# N32G41x register map
Vendor: Nsingtech Ltd.; File version: 1.0
CPU: CM4 r0p1, little endian, no MPU, no FPU, 4 interrupt priority bits
Registers are 32-bit, read-write, reset 0x0 unless marked. A register's access mark holds for its fields unless they carry their own. Offsets are from the block's base; [hi:lo] are bit positions.

## IWDG — Independent Watchdog
Base 0x40003000
0x00 IWDG_KEY
  [15:0] KEYV — Key value
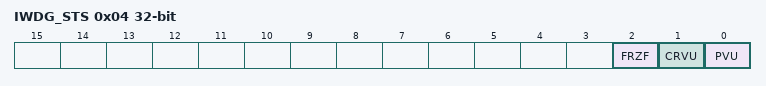
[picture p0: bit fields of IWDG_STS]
0x04 IWDG_STS ro — IWDG Status Register
  [2] FRZF — IWDG freeze flag
  [1] CRVU — Watchdog reload value update
  [0] PVU — Watchdog prescaler value update
0x08 IWDG_PREDIV — IWDG Prescaler Register
  [2:0] PD — Prescaler divider
0x0C IWDG_RELV reset 0xFFF — IWDG Reload Register
  [11:0] REL — Watchdog counter reload value

## SPI1_I2S — Serial Peripheral Interface 1
Base 0x40013000
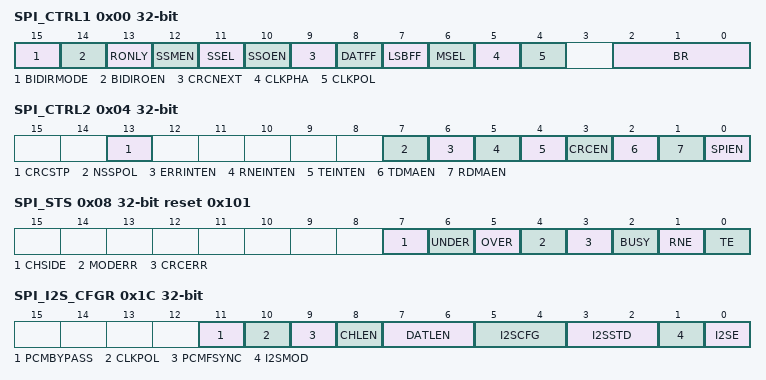
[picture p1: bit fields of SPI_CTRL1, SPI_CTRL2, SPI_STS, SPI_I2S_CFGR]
0x00 SPI_CTRL1 — SPI Control Register 1
  [15] BIDIRMODE — Bidirectional data mode enable
  [14] BIDIROEN — Output enable in bidirectional mode
  [13] RONLY — Receive only
  [12] SSMEN — Software slave management
  [11] SSEL — Internal slave select
  [10] SSOEN — SS output enable
  [9] CRCNEXT — Next CRC transmit
  [8] DATFF — Data frame format
  [7] LSBFF — Frame format
  [6] MSEL — Master selection
  [5] CLKPHA — Clock phase
  [4] CLKPOL — Clock polarity
  [2:0] BR — Baud rate control
0x04 SPI_CTRL2 — SPI Control Register 2
  [13] CRCSTP — CRC stop after NSS inactive
  [7] NSSPOL — NSS polarity control
  [6] ERRINTEN — Error interrupt enable
  [5] RNEINTEN — RX buffer not empty interrupt enable
  [4] TEINTEN — TX buffer empty interrupt enable
  [3] CRCEN — Hardware CRC calculation enable
  [2] TDMAEN — TX buffer DMA enable
  [1] RDMAEN — RX buffer DMA enable
  [0] SPIEN — SPI enable
0x08 SPI_STS ro reset 0x101 — SPI Status Register
  [7] CHSIDE — Channel side
  [6] UNDER — Underrun flag
  [5] OVER — Overrun flag
  [4] MODERR — Mode error
  [3] CRCERR — CRC error flag
  [2] BUSY — Busy flag
  [1] RNE — Receive buffer not empty
  [0] TE — Transmit buffer empty
0x0C SPI_DAT — SPI Data Register
  [15:0] DAT — Data register
0x10 SPI_CRCTDAT ro — SPI TX CRC Register
  [15:0] CRCTDAT — TX CRC value
0x14 SPI_CRCRDAT ro — SPI RX CRC Register
  [15:0] CRCRDAT — RX CRC value
0x18 SPI_CRCPOLY reset 0x7 — SPI CRC Polynomial Register
  [15:0] CRCPOLY — CRC polynomial
0x1C SPI_I2S_CFGR — SPI-I2S Configuration Register
  [11] PCMBYPASS — PCM bypass mode
  [10] CLKPOL — I2S clock polarity in idle state
  [9] PCMFSYNC — PCM frame synchronization
  [8] CHLEN — Channel length
  [7:6] DATLEN — Data length to be transferred
  [5:4] I2SCFG — I2S mode configuration
  [3:2] I2SSTD — I2S standard selection
  [1] I2SMOD — I2S mode selection
  [0] I2SE — I2S enable
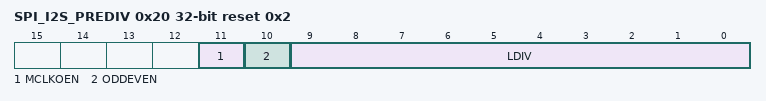
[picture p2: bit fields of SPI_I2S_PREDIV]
0x20 SPI_I2S_PREDIV reset 0x2 — SPI-I2S Prescaler Register
  [11] MCLKOEN — Master clock output enable
  [10] ODDEVEN — Odd factor prescaler
  [9:0] LDIV — I2S linear prescaler
0x38 SPI_CTRL3 — SPI Sampling Delay Register
  [3:0] DELAYTIME — SPI master sampling delay time configuration

## SPI2 — Serial Peripheral Interface 2
Base 0x40013C00
Registers as SPI1_I2S, without SPI_I2S_CFGR, SPI_I2S_PREDIV; these are added or differ:
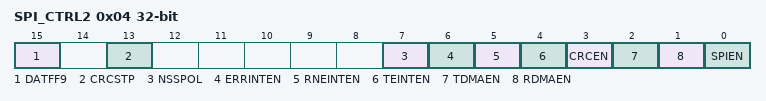
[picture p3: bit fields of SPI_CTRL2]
0x04 SPI_CTRL2 — SPI Control Register 2
  [15] DATFF9 — 9-bit data frame format enable
  [13] CRCSTP — CRC stop after NSS inactive
  [7] NSSPOL — NSS polarity control
  [6] ERRINTEN — Error interrupt enable
  [5] RNEINTEN — RX buffer not empty interrupt enable
  [4] TEINTEN — TX buffer empty interrupt enable
  [3] CRCEN — Hardware CRC calculation enable
  [2] TDMAEN — TX buffer DMA enable
  [1] RDMAEN — RX buffer DMA enable
  [0] SPIEN — SPI enable

## USART1 — Universal Synchronous Asynchronous Receiver Transmitter
Base 0x40013800
Same registers: USART2 0x40004400, USART3 0x40004800, USART4 0x40015000
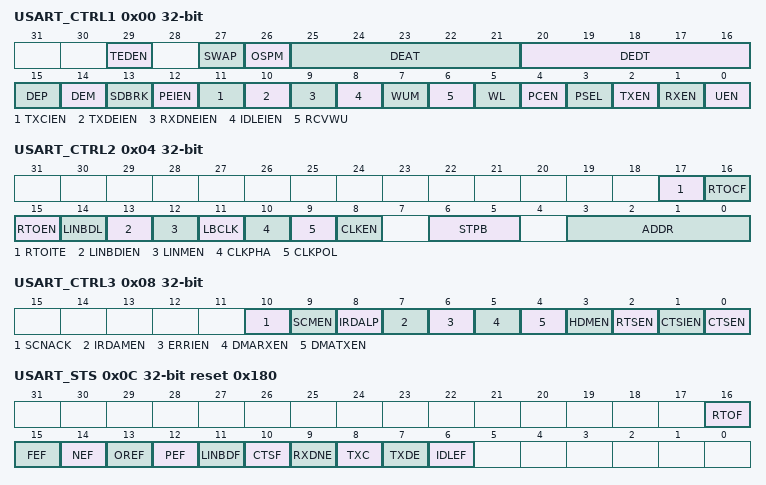
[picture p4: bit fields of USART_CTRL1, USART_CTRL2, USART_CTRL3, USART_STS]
0x00 USART_CTRL1 — USART Control Register 1
  [29] TEDEN — TX enable delay
  [27] SWAP — Swap TX/RX pins
  [26] OSPM — Oversampling mode
  [25:21] DEAT — Driver enable assertion time
  [20:16] DEDT — Driver enable deassertion time
  [15] DEP — Driver enable polarity
  [14] DEM — Driver enable mode
  [13] SDBRK — Send break
  [12] PEIEN — PE interrupt enable
  [11] TXCIEN — TX complete interrupt enable
  [10] TXDEIEN — TX data empty interrupt enable
  [9] RXDNEIEN — RX data not empty interrupt enable
  [8] IDLEIEN — IDLE line interrupt enable
  [7] WUM — Wake up mode
  [6] RCVWU — Receiver wakeup
  [5] WL — Word length
  [4] PCEN — Parity control enable
  [3] PSEL — Parity selection
  [2] TXEN — Transmitter enable
  [1] RXEN — Receiver enable
  [0] UEN — USART enable
0x04 USART_CTRL2 — USART Control Register 2
  [17] RTOITE — Receiver timeout interrupt enable
  [16] RTOCF — Receiver timeout clear flag
  [15] RTOEN — Receiver timeout enable
  [14] LINBDL — LIN break detection length
  [13] LINBDIEN — LIN break detection interrupt enable
  [12] LINMEN — LIN mode enable
  [11] LBCLK — Last bit clock pulse
  [10] CLKPHA — Clock phase
  [9] CLKPOL — Clock polarity
  [8] CLKEN — Clock enable
  [6:5] STPB — STOP bits
  [3:0] ADDR — USART address
0x08 USART_CTRL3 — USART Control Register 3
  [10] SCNACK — Smartcard NACK enable
  [9] SCMEN — Smartcard mode enable
  [8] IRDALP — IrDA low-power
  [7] IRDAMEN — IrDA mode enable
  [6] ERRIEN — Error interrupt enable
  [5] DMARXEN — DMA receiver enable
  [4] DMATXEN — DMA transmitter enable
  [3] HDMEN — Half-duplex mode enable
  [2] RTSEN — RTS enable
  [1] CTSIEN — CTS interrupt enable
  [0] CTSEN — CTS enable
0x0C USART_STS reset 0x180 — USART Status Register
  [16] RTOF ro — Receiver timeout
  [15] FEF ro — Framing error
  [14] NEF ro — Noise error flag
  [13] OREF ro — Overrun error
  [12] PEF ro — Parity error
  [11] LINBDF — LIN break detection flag
  [10] CTSF — CTS flag
  [9] RXDNE — Read data register not empty
  [8] TXC — Transmission complete
  [7] TXDE ro — Transmit data register empty
  [6] IDLEF ro — IDLE line detected
0x10 USART_DAT — USART Data Register
  [8:0] DATV — Data value
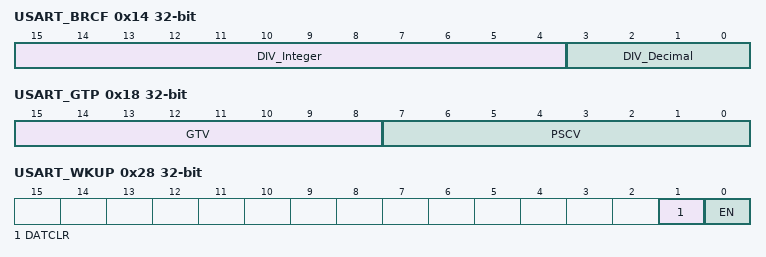
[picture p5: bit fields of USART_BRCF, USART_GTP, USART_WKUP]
0x14 USART_BRCF — USART Baud Rate Configuration Register
  [15:4] DIV_Integer — Divider integer part
  [3:0] DIV_Decimal — Divider decimal part
0x18 USART_GTP — USART Guard Time and Prescaler Register
  [15:8] GTV — Guard time value
  [7:0] PSCV — Prescaler value
0x24 USART_RTO — USART Receiver Timeout Register
  [27:0] TIME — Receiver timeout value
0x28 USART_WKUP — USART Low Power Wakeup Register
  [1] DATCLR — Clear received wakeup data
  [0] EN — Wakeup enable
